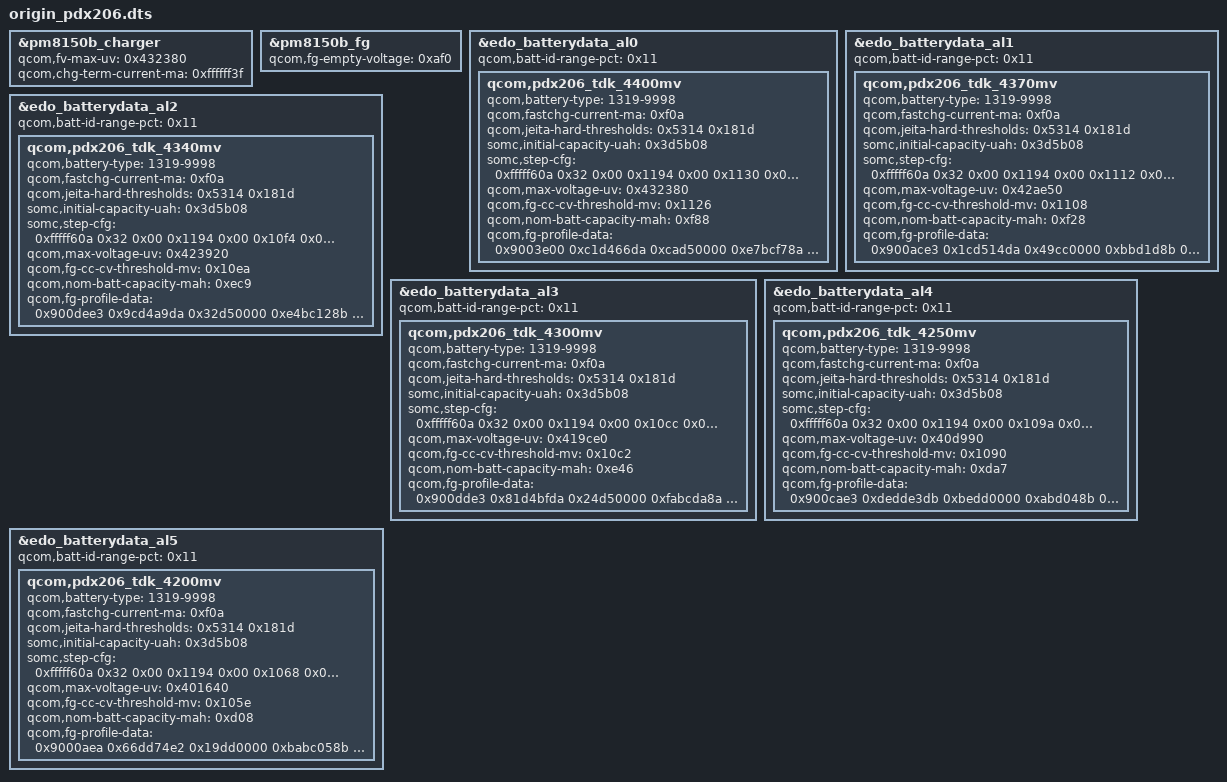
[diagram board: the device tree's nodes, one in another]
/dts-v1/;
/plugin/;

&pm8150b_charger {
	qcom,fv-max-uv = <0x432380>;
	qcom,chg-term-current-ma = <0xffffff3f>;
};
&pm8150b_fg  {
	qcom,fg-empty-voltage = <0xaf0>;
};
&edo_batterydata_al0 {
	qcom,batt-id-range-pct = <0x11>;
	qcom,pdx206_tdk_4400mv {
		qcom,battery-type = "1319-9998";
		qcom,fastchg-current-ma = <0xf0a>;
		qcom,jeita-hard-thresholds = <0x5314 0x181d>;
		somc,initial-capacity-uah = <0x3d5b08>;
		somc,step-cfg = <0xfffff60a 0x32 0x00 0x1194 0x00 0x1130 0x01 0x32 0x78 0x00 0x1194 0x2ee 0x1130 0x02 0x78 0xc8 0x00 0x1004 0x8fc 0x1130 0x03 0x78 0xc8 0x1004 0x1068 0x76c 0x1130 0x03 0x78 0xc8 0x1068 0x10cc 0x5dc 0x1130 0x03 0x78 0xc8 0x10cc 0x1194 0x47e 0x1130 0x03 0xc8 0x1c2 0x00 0x1036 0xf0a 0x1130 0x03 0xc8 0x1c2 0x1036 0x1068 0xb22 0x1130 0x03 0xc8 0x1c2 0x1068 0x10cc 0x76c 0x1130 0x03 0xc8 0x1c2 0x10cc 0x1194 0x47e 0x1130 0x03 0x1c2 0x226 0x00 0x1194 0x47e 0x1068 0x04 0x226 0x9f6 0x00 0x1194 0x00 0x1068 0x05>;
		qcom,max-voltage-uv = <0x432380>;
		qcom,fg-cc-cv-threshold-mv = <0x1126>;
		qcom,nom-batt-capacity-mah = <0xf88>;
		qcom,fg-profile-data = <0x9003e00 0xc1d466da 0xcad50000 0xe7bcf78a 0xfb87948b 0x3f9d6880 0x2000dbfa 0x4813d7fd 0xfe5ce07 0x32005b00 0xa3ed27d3 0x840a35e5 0x49c50112 0xe301a9d2 0x60004b00 0x4c004800 0x28002f00 0x37003c00 0x40004100 0x40006000 0x35004100 0x48004400 0x3d009000 0x5f644e00 0x44004008 0x60f84c00 0x47006c10 0x55104800 0x99286948 0x56604a0c 0x4800d800 0x7b1fbc0d 0x2b02a705 0x801c4a0b 0xa30d9122 0x27183142 0x50554902 0x6711781f 0xcf05330a 0xae06e21c 0xfc01b505 0x90027618 0x3f230c45 0xb1537711 0x4c1ffde5 0x1bc2b896 0xdc1ca2b9 0xf2048abb 0x3a184893 0x16858c9b 0x80980980 0xbaebbf04 0x59fce203 0x83dc 0x49e2f0ff 0x23bb04ad 0x181019f0 0x94c59303 0x17059f00 0xce073200 0x6a017602 0xf8051f02 0x7050305 0xa0038602 0x14044400 0x3d004c00 0x50645400 0x52005208 0x54f85200 0x55006808 0x34084200 0x55285248 0x5e586f0d 0x48005900 0x5d086100 0x54004200 0x4b085608 0x4e006228 0x7a484660 0x590d6100 0x61004908 0xd8f85d20 0x5705520a 0x270d091d 0xab22a244 0x555b9418 0x1102a405 0xb703780f 0x3f0a3820 0x1405c202 0x1b06d91c 0xc7025504 0xe3038518 0x16028705 0x6027100 0x531fff05 0x2b023905 0xdb1c5902 0xf054f03 0xa7186703 0x9f045102 0x6d000d01 0xc000fa00 0xb50f0000>;
	};
};
&edo_batterydata_al1 {
	qcom,batt-id-range-pct = <0x11>;
	qcom,pdx206_tdk_4370mv {
		qcom,battery-type = "1319-9998";
		qcom,fastchg-current-ma = <0xf0a>;
		qcom,jeita-hard-thresholds = <0x5314 0x181d>;
		somc,initial-capacity-uah = <0x3d5b08>;
		somc,step-cfg = <0xfffff60a 0x32 0x00 0x1194 0x00 0x1112 0x01 0x32 0x78 0x00 0x1194 0x2ee 0x1112 0x02 0x78 0xc8 0x00 0x1004 0x8fc 0x1112 0x03 0x78 0xc8 0x1004 0x1068 0x6a4 0x1112 0x03 0x78 0xc8 0x1068 0x10cc 0x5dc 0x1112 0x03 0x78 0xc8 0x10cc 0x1194 0x47e 0x1112 0x03 0xc8 0x1c2 0x00 0x1036 0xd7a 0x1112 0x03 0xc8 0x1c2 0x1036 0x1068 0xa8c 0x1112 0x03 0xc8 0x1c2 0x1068 0x10cc 0x76c 0x1112 0x03 0xc8 0x1c2 0x10cc 0x1194 0x47e 0x1112 0x03 0x1c2 0x226 0x00 0x1194 0x47e 0x1068 0x04 0x226 0x9f6 0x00 0x1194 0x00 0x1068 0x05>;
		qcom,max-voltage-uv = <0x42ae50>;
		qcom,fg-cc-cv-threshold-mv = <0x1108>;
		qcom,nom-batt-capacity-mah = <0xf28>;
		qcom,fg-profile-data = <0x900ace3 0x1cd514da 0x49cc0000 0xbbd1d8b 0xf987568a 0x749d6880 0x220095fa 0x1b13aa06 0x1be2ce07 0x3200f9ea 0x86ed3bd3 0x8c0a42e5 0x2dc5b50b 0xa1fb54d2 0x60004d00 0x4c004900 0x2e002e00 0x36003b00 0x41004100 0x40006000 0x34004100 0x49004500 0x3b008800 0x5c644d00 0x41003f08 0x60f84d00 0x48006710 0x56104500 0xa0286d48 0x5660480c 0x4100d800 0x9a1f8f0d 0x4e024305 0x6f1c7803 0x7c05b322 0xe3174b42 0x31556302 0x67111421 0x2104510b 0xaafdf51c 0xa001dd04 0x74036b18 0x37232545 0x79539012 0x3c1f0de6 0xdc271b5 0xd61cadc1 0xca04a2bb 0x7d18ed92 0x8d85d2a2 0x7fa00980 0x8ceb6c04 0x55050403 0xccd4 0x22eaf107 0x68e2c1cd 0x17181a00 0x11e52303 0x7d06ae00 0xce073200 0x8c01ac03 0xf3054601 0x31045e02 0x4402e802 0x6d054200 0x3c004d00 0x50645500 0x54005008 0x56005300 0x54005510 0x36104200 0x56285148 0x5f60700c 0x48005700 0x65086b00 0x50004300 0x4b085808 0x4f006128 0x7d484758 0x550d6100 0x5f004208 0xd8f8e61f 0xce05050a 0xc90ed51c 0x5423b145 0x5b5a6918 0x51020905 0xa0026a10 0x3f0abf20 0x79042f03 0xad05db1c 0xad029804 0x81038a18 0x102b705 0x99037800 0xc21f7c05 0x8a026b04 0xde1c3502 0x6505d802 0xa9184c03 0xd3041c02 0x75000501 0xc000fa00 0x510f0000>;
	};
};
&edo_batterydata_al2 {
	qcom,batt-id-range-pct = <0x11>;
	qcom,pdx206_tdk_4340mv {
		qcom,battery-type = "1319-9998";
		qcom,fastchg-current-ma = <0xf0a>;
		qcom,jeita-hard-thresholds = <0x5314 0x181d>;
		somc,initial-capacity-uah = <0x3d5b08>;
		somc,step-cfg = <0xfffff60a 0x32 0x00 0x1194 0x00 0x10f4 0x01 0x32 0x78 0x00 0x1194 0x2ee 0x10f4 0x02 0x78 0xc8 0x00 0x1004 0x8fc 0x10f4 0x03 0x78 0xc8 0x1004 0x1068 0x6a4 0x10f4 0x03 0x78 0xc8 0x1068 0x10cc 0x5dc 0x10f4 0x03 0x78 0xc8 0x10cc 0x1194 0x47e 0x10f4 0x03 0xc8 0x1c2 0x00 0x1036 0xd7a 0x10f4 0x03 0xc8 0x1c2 0x1036 0x1068 0xa8c 0x10f4 0x03 0xc8 0x1c2 0x1068 0x10cc 0x76c 0x10f4 0x03 0xc8 0x1c2 0x10cc 0x1194 0x47e 0x10f4 0x03 0x1c2 0x226 0x00 0x1194 0x47e 0x1068 0x04 0x226 0x9f6 0x00 0x1194 0x00 0x1068 0x05>;
		qcom,max-voltage-uv = <0x423920>;
		qcom,fg-cc-cv-threshold-mv = <0x10ea>;
		qcom,nom-batt-capacity-mah = <0xec9>;
		qcom,fg-profile-data = <0x900dee3 0x9cd4a9da 0x32d50000 0xe4bc128b 0xfa878980 0x518d4580 0x2300b901 0xee1227fd 0x3ce2ce07 0x32006300 0x59edabd2 0x910a36e5 0x3bc5dc0b 0xe1fb03d2 0x60004c00 0x4e004900 0x33002f00 0x37003e00 0x48004300 0x41006000 0x34004300 0x46004500 0x3a007b00 0x5c644d00 0x41003c08 0x60005100 0x4c006510 0x5b104700 0xa2287648 0x59584b0d 0x4500d800 0xa71f8b0d 0x4502a6fe 0x8a1c1b03 0xd3054b22 0x26180d42 0xac55a903 0x6b111821 0x2afc3b03 0xbffdf91c 0x35fbe204 0x5c03b118 0xa234e45 0x47539112 0x351f45e4 0xd6c3b3bd 0xdd1c31c3 0x50553bb 0x5c180593 0x7785eb9a 0x82980980 0xb4db2d05 0x71fdbbf2 0xf87ddc 0x60e2efff 0x93db9fbc 0x191019f0 0x6ad59803 0xd1044203 0xce073200 0x3035e03 0x505d303 0x93055d03 0x33037b03 0x37044400 0x3b004e00 0x51645600 0x54005300 0x54005300 0x54004808 0x35084200 0x56285348 0x60586f0d 0x4b005500 0x61086400 0x50003e00 0x49105710 0x50005e28 0x7b484b58 0x510d6000 0x63004808 0xd8000f20 0xbefdee0b 0xde0ef71c 0xd1226a44 0x7c539118 0xc02ac05 0xab037510 0x3f0ae31f 0x7d056502 0x6506bd1c 0x1d03d905 0x42028018 0xe029405 0xf4036b00 0x5f20e304 0xdf02ef05 0xe91cfd03 0xd7054502 0xaf183303 0x105dc03 0x82000d01 0xc000fa00 0xfb0e0000>;
	};
};
&edo_batterydata_al3 {
	qcom,batt-id-range-pct = <0x11>;
	qcom,pdx206_tdk_4300mv {
		qcom,battery-type = "1319-9998";
		qcom,fastchg-current-ma = <0xf0a>;
		qcom,jeita-hard-thresholds = <0x5314 0x181d>;
		somc,initial-capacity-uah = <0x3d5b08>;
		somc,step-cfg = <0xfffff60a 0x32 0x00 0x1194 0x00 0x10cc 0x01 0x32 0x78 0x00 0x1194 0x2ee 0x10cc 0x02 0x78 0xc8 0x00 0x1004 0x8fc 0x10cc 0x03 0x78 0xc8 0x1004 0x1068 0x5dc 0x10cc 0x03 0x78 0xc8 0x1068 0x1194 0x546 0x10cc 0x03 0xc8 0x1c2 0x00 0x1036 0xbea 0x10cc 0x03 0xc8 0x1c2 0x1036 0x1068 0x8fc 0x10cc 0x03 0xc8 0x1c2 0x1068 0x1194 0x5dc 0x10cc 0x03 0x1c2 0x226 0x00 0x1194 0x47e 0x1068 0x04 0x226 0x9f6 0x00 0x1194 0x00 0x1068 0x05>;
		qcom,max-voltage-uv = <0x419ce0>;
		qcom,fg-cc-cv-threshold-mv = <0x10c2>;
		qcom,nom-batt-capacity-mah = <0xe46>;
		qcom,fg-profile-data = <0x900dde3 0x81d4bfda 0x24d50000 0xfabcda8a 0xfc872b82 0xcb9d7b80 0x200077fb 0xee12e606 0xd5e4ce07 0x32006600 0x42ed93d3 0xb50a66e5 0x1ec5b60a 0x970164cb 0x60004d00 0x4d004a00 0x37002d00 0x36004100 0x4e004100 0x3e006000 0x36004400 0x48004900 0x3d005c00 0x64645200 0x42003d08 0x60f85000 0x4c005708 0x5d084900 0x71207040 0x58584a0e 0x4400d808 0x2620130d 0x8402dbfc 0x8e1cde02 0x4804af23 0x4e18b343 0x1754dc02 0x77131522 0xa005bc0b 0x5405f41c 0x1ffb1b05 0xff02a818 0xd022b545 0x92529c13 0x1b2146e4 0xdc3e4ad 0xe21ccfc2 0xca0561ba 0x4e18fb92 0x8f85bd9a 0x9e980980 0xb7e3d404 0x46fc2af2 0x93dc 0x3ee2f007 0xe1eafed4 0x27101900 0xb2e59d03 0xd057d02 0xce073200 0x9901d603 0x1b044802 0x89051102 0xe2029302 0x92044400 0x3b004d00 0x4f645300 0x53f84f00 0x51f05300 0x52005008 0x33084000 0x54285148 0x5b586a0d 0x5a004b00 0x560861f8 0x4c004100 0x47085508 0x52005b20 0x76406458 0x4c0e5d00 0x63004408 0xd800a81f 0x8104130b 0xe90ce51c 0xf2223944 0xa1538918 0x802b105 0xa2037110 0x3f0a4120 0x22059502 0x6904d11c 0xbf027704 0x8c03a118 0xa4032604 0xd2027500 0x7d1fe205 0x1c029b06 0xcc1c5d02 0x2505f902 0xaf182303 0x1505c103 0x73000e01 0xc000fa00 0x870e0000>;
	};
};
&edo_batterydata_al4 {
	qcom,batt-id-range-pct = <0x11>;
	qcom,pdx206_tdk_4250mv {
		qcom,battery-type = "1319-9998";
		qcom,fastchg-current-ma = <0xf0a>;
		qcom,jeita-hard-thresholds = <0x5314 0x181d>;
		somc,initial-capacity-uah = <0x3d5b08>;
		somc,step-cfg = <0xfffff60a 0x32 0x00 0x1194 0x00 0x109a 0x01 0x32 0x78 0x00 0x1194 0x2ee 0x109a 0x02 0x78 0xc8 0x00 0x1004 0x76c 0x109a 0x03 0x78 0xc8 0x1004 0x1068 0x546 0x109a 0x03 0x78 0xc8 0x1068 0x1194 0x47e 0x109a 0x03 0xc8 0x1c2 0x00 0x1036 0xa8c 0x109a 0x03 0xc8 0x1c2 0x1036 0x1068 0x76c 0x109a 0x03 0xc8 0x1c2 0x1068 0x1194 0x5dc 0x109a 0x03 0x1c2 0x226 0x00 0x1194 0x47e 0x1068 0x04 0x226 0x9f6 0x00 0x1194 0x00 0x1068 0x05>;
		qcom,max-voltage-uv = <0x40d990>;
		qcom,fg-cc-cv-threshold-mv = <0x1090>;
		qcom,nom-batt-capacity-mah = <0xda7>;
		qcom,fg-profile-data = <0x900cae3 0xdedde3db 0xbedd0000 0xabd048b 0xf987a78c 0x928c7580 0x2700effb 0x98121206 0xabf2ce07 0x320013f2 0xceec43b2 0x660b9ae5 0x5dc4cc03 0x63fbceca 0x60004600 0x45004300 0x42002600 0x35004600 0x3e004300 0x44006000 0x29003500 0x3f004200 0x37003800 0x59644300 0x3b003308 0x60005000 0x4d004710 0x65104900 0x4b207348 0x5658480d 0x4100d800 0x2420210d 0x63028806 0x691c3303 0xe7050422 0x3a18ec43 0xc8557d03 0x76125420 0x1405740a 0x6706e71c 0xbd016f04 0x87038c18 0xf0228b45 0xd3528d13 0x2a2043e5 0x55c27bbe 0xdb1c7cb1 0x7b058eba 0x8018c792 0xcb85699a 0x96980980 0x99db7704 0x6a02a602 0xf8b3e4 0x3beaf007 0x4b021ea5 0x38081ad8 0x1adaba03 0x6406ca00 0xce073200 0x49034f02 0x71056c02 0x3300f203 0x4703e504 0xee054400 0x3a004d00 0x4f645300 0x55005000 0x51e05200 0x52004308 0x33083f00 0x54285248 0x5b58670d 0x6f004800 0x5a086500 0x52003f00 0x45085408 0x54005720 0x72407458 0x460f5900 0x60004f08 0xd800451f 0xda06ef01 0x9c04df1c 0xe9226544 0x56538318 0x802b105 0xa2037112 0x3f0a3d21 0x2b042203 0xb905e01c 0x73021d05 0xb602ae18 0x6703a004 0x50028500 0x48212004 0x2a03b405 0xec1cd601 0x58048503 0xc118e502 0x8505ef02 0x92000e01 0xc000fa00 0xe40d0000>;
	};
};
&edo_batterydata_al5 {
	qcom,batt-id-range-pct = <0x11>;
	qcom,pdx206_tdk_4200mv {
		qcom,battery-type = "1319-9998";
		qcom,fastchg-current-ma = <0xf0a>;
		qcom,jeita-hard-thresholds = <0x5314 0x181d>;
		somc,initial-capacity-uah = <0x3d5b08>;
		somc,step-cfg = <0xfffff60a 0x32 0x00 0x1194 0x00 0x1068 0x01 0x32 0x78 0x00 0x1194 0x2ee 0x1068 0x02 0x78 0xc8 0x00 0x1004 0x76c 0x1068 0x03 0x78 0xc8 0x1004 0x1194 0x546 0x1068 0x03 0xc8 0x1c2 0x00 0x1036 0xa8c 0x1068 0x03 0xc8 0x1c2 0x1036 0x1194 0x76c 0x1068 0x03 0x1c2 0x226 0x00 0x1194 0x47e 0x1068 0x04 0x226 0x9f6 0x00 0x1194 0x00 0x1068 0x05>;
		qcom,max-voltage-uv = <0x401640>;
		qcom,fg-cc-cv-threshold-mv = <0x105e>;
		qcom,nom-batt-capacity-mah = <0xd08>;
		qcom,fg-profile-data = <0x9000aea 0x66dd74e2 0x19dd0000 0xbabc058b 0xfb87c89d 0x73878680 0x25000402 0xa312bffc 0x8deace07 0x32002ff2 0x8aec20c5 0x360b01dd 0xc7c4050a 0x84016cc3 0x60004500 0x45004400 0x44002a00 0x33003f00 0x3b004500 0x2c006000 0x29003500 0x40004300 0x3a003600 0x5e644200 0x3c003508 0x60005400 0x4e004808 0x6b084e00 0x47207a40 0x5a58490f 0x4600d800 0xa420c70c 0x76028306 0x8c1ca502 0xdc04d322 0x53188c43 0x60549102 0x86136d21 0x130cfd0a 0xf505e01c 0xb6f9aa04 0x16038218 0xcc22c945 0x6b529b14 0xd82264e5 0xc8c34bc5 0xdf1cbdc2 0xde050dba 0x5b18bb92 0xee852792 0xae800980 0xe5c34c04 0xcf03b3f5 0x13ec 0xadf2ec07 0x4cec38b7 0x68081a00 0xde4b303 0x58067203 0xce073200 0xc5016203 0xa3041207 0x51022d04 0xc4032e02 0x37044900 0x3a004f00 0x51645600 0x59e859e8 0x57f05700 0x5c005308 0x33083b00 0x53205040 0x5758610f 0x70004700 0x530866f8 0x69003c00 0x41085208 0x59005320 0x6a407b58 0x450f5300 0x6a005e08 0xd8f8301e 0x6a02150c 0xa90bea1c 0xa222eb44 0xc4529218 0xa4034604 0xa4026912 0x3f0acf20 0xc1049c02 0x6104ce1c 0x8e020105 0xb502a118 0x6503a404 0x4d028400 0xe71f9e05 0x12024905 0xd61c1002 0xc7051602 0xc418c502 0xb405a302 0x84001401 0xc000fa00 0x3e0d0000>;
	};
};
